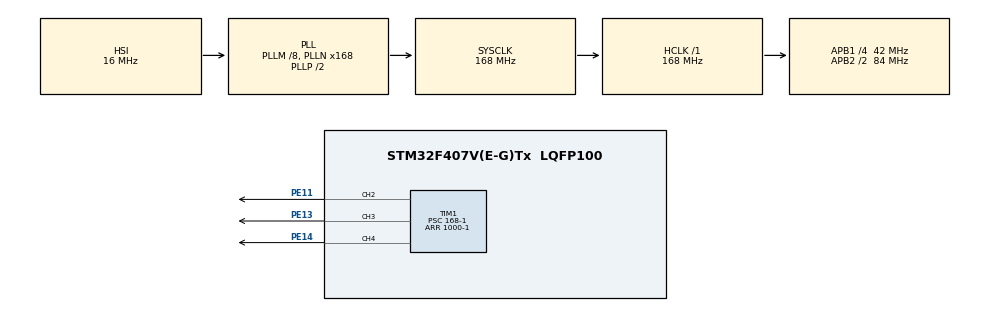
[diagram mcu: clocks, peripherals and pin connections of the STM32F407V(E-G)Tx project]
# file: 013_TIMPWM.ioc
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Mcu.Family=STM32F4
Mcu.Name=STM32F407V(E-G)Tx
Mcu.Package=LQFP100
NVIC.PriorityGroup=NVIC_PRIORITYGROUP_4
PE11.Signal=S_TIM1_CH2
PE13.Signal=S_TIM1_CH3
PE14.Signal=S_TIM1_CH4
ProjectManager.HeapSize=0x200
ProjectManager.StackSize=0x400
ProjectManager.TargetToolchain=EWARM V8.50
RCC.48MHZClocksFreq_Value=84000000
RCC.AHBFreq_Value=168000000
RCC.APB1CLKDivider=RCC_HCLK_DIV4
RCC.APB1Freq_Value=42000000
RCC.APB1TimFreq_Value=84000000
RCC.APB2CLKDivider=RCC_HCLK_DIV2
RCC.APB2Freq_Value=84000000
RCC.APB2TimFreq_Value=168000000
RCC.CortexFreq_Value=168000000
RCC.HCLKFreq_Value=168000000
RCC.HSE_VALUE=25000000
RCC.HSI_VALUE=16000000
RCC.LSE_VALUE=32768
RCC.PLLM=8
RCC.PLLN=168
RCC.SYSCLKFreq_VALUE=168000000
RCC.SYSCLKSource=RCC_SYSCLKSOURCE_PLLCLK
RCC.VCOOutputFreq_Value=336000000
SH.S_TIM1_CH2.0=TIM1_CH2,PWM Generation2 CH2
SH.S_TIM1_CH3.0=TIM1_CH3,PWM Generation3 CH3
SH.S_TIM1_CH4.0=TIM1_CH4,PWM Generation4 CH4
TIM1.Channel-PWM\ Generation2\ CH2=TIM_CHANNEL_2
TIM1.Channel-PWM\ Generation3\ CH3=TIM_CHANNEL_3
TIM1.Channel-PWM\ Generation4\ CH4=TIM_CHANNEL_4
TIM1.Period=1000-1
TIM1.Prescaler=168-1
VP_TIM1_VS_ClockSourceINT.Mode=Internal
board=custom

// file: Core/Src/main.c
/* USER CODE BEGIN Header */
/**
  ******************************************************************************
  * @file           : main.c
  * @brief          : Main program body
  ******************************************************************************
  * @attention
  *
  * Copyright (c) 2026 STMicroelectronics.
  * All rights reserved.
  *
  * This software is licensed under terms that can be found in the LICENSE file
  * in the root directory of this software component.
  * If no LICENSE file comes with this software, it is provided AS-IS.
  *
  ******************************************************************************
  */
/* USER CODE END Header */
#include "main.h"
#include "tim.h"
#include "gpio.h"

/* USER CODE BEGIN PV */

static uint8_t LED0State = 0;
static uint8_t LED1State = 0;
static uint8_t LED2State = 0;

/* USER CODE END PV */

void SystemClock_Config(void);

int main(void)
{

  /* MCU Configuration--------------------------------------------------------*/

  /* Reset of all peripherals, Initializes the Flash interface and the Systick. */
  HAL_Init();

  /* Configure the system clock */
  SystemClock_Config();

  /* Initialize all configured peripherals */
  MX_GPIO_Init();
  MX_TIM1_Init();
  /* USER CODE BEGIN 2 */

  HAL_TIM_PWM_Start_IT(&htim1, TIM_CHANNEL_2);
  HAL_TIM_PWM_Start_IT(&htim1, TIM_CHANNEL_3);
  HAL_TIM_PWM_Start_IT(&htim1, TIM_CHANNEL_4);

  __HAL_TIM_SET_COMPARE(&htim1, TIM_CHANNEL_2, 10);
  __HAL_TIM_SET_COMPARE(&htim1, TIM_CHANNEL_3, 10);
  __HAL_TIM_SET_COMPARE(&htim1, TIM_CHANNEL_4, 10);

  /* USER CODE END 2 */

  /* Infinite loop */
  /* USER CODE BEGIN WHILE */
  while (1)
  {
    // REGISTRY

    TIM1->CCR2 += LED0State ? -1 : 1;
    TIM1->CCR3 += LED1State ? -1 : 1;
    TIM1->CCR4 += LED2State ? -1 : 1;

    if (TIM1->CCR2 == 0 || TIM1->CCR2 == 999) {
      LED0State = !LED0State;
    }
    if (TIM1->CCR3 == 0 || TIM1->CCR3 == 999) {
      LED1State = !LED1State;
    }
    if (TIM1->CCR4 == 0 || TIM1->CCR4 == 999) {
      LED2State = !LED2State;
    }

    // HAL

    /*
    __HAL_TIM_SET_COMPARE(&htim1, TIM_CHANNEL_2, __HAL_TIM_GET_COMPARE(&htim1, TIM_CHANNEL_2) + (LED0State ? -1 : 1));
    __HAL_TIM_SET_COMPARE(&htim1, TIM_CHANNEL_3, __HAL_TIM_GET_COMPARE(&htim1, TIM_CHANNEL_3) + (LED1State ? -1 : 1));
    __HAL_TIM_SET_COMPARE(&htim1, TIM_CHANNEL_4, __HAL_TIM_GET_COMPARE(&htim1, TIM_CHANNEL_4) + (LED2State ? -1 : 1));

    if (__HAL_TIM_GET_COMPARE(&htim1, TIM_CHANNEL_2) == 0 || __HAL_TIM_GET_COMPARE(&htim1, TIM_CHANNEL_2) == 999) {
      LED0State = !LED0State;
    }
    if (__HAL_TIM_GET_COMPARE(&htim1, TIM_CHANNEL_3) == 0 || __HAL_TIM_GET_COMPARE(&htim1, TIM_CHANNEL_3) == 999) {
      LED1State = !LED1State;
    }
    if (__HAL_TIM_GET_COMPARE(&htim1, TIM_CHANNEL_4) == 0 || __HAL_TIM_GET_COMPARE(&htim1, TIM_CHANNEL_4) == 999) {
      LED2State = !LED2State;
    }
    */
    HAL_Delay(1);
    /* USER CODE END WHILE */

  }
}

void SystemClock_Config(void)
{
  RCC_OscInitTypeDef RCC_OscInitStruct = {0};
  RCC_ClkInitTypeDef RCC_ClkInitStruct = {0};

  /** Configure the main internal regulator output voltage
  */
  __HAL_RCC_PWR_CLK_ENABLE();
  __HAL_PWR_VOLTAGESCALING_CONFIG(PWR_REGULATOR_VOLTAGE_SCALE1);

  /** Initializes the RCC Oscillators according to the specified parameters
  * in the RCC_OscInitTypeDef structure.
  */
  RCC_OscInitStruct.OscillatorType = RCC_OSCILLATORTYPE_HSI;
  RCC_OscInitStruct.HSIState = RCC_HSI_ON;
  RCC_OscInitStruct.HSICalibrationValue = RCC_HSICALIBRATION_DEFAULT;
  RCC_OscInitStruct.PLL.PLLState = RCC_PLL_ON;
  RCC_OscInitStruct.PLL.PLLSource = RCC_PLLSOURCE_HSI;
  RCC_OscInitStruct.PLL.PLLM = 8;
  RCC_OscInitStruct.PLL.PLLN = 168;
  RCC_OscInitStruct.PLL.PLLP = RCC_PLLP_DIV2;
  RCC_OscInitStruct.PLL.PLLQ = 4;
  if (HAL_RCC_OscConfig(&RCC_OscInitStruct) != HAL_OK)
  {
    Error_Handler();
  }

  /** Initializes the CPU, AHB and APB buses clocks
  */
  RCC_ClkInitStruct.ClockType = RCC_CLOCKTYPE_HCLK|RCC_CLOCKTYPE_SYSCLK
                              |RCC_CLOCKTYPE_PCLK1|RCC_CLOCKTYPE_PCLK2;
  RCC_ClkInitStruct.SYSCLKSource = RCC_SYSCLKSOURCE_PLLCLK;
  RCC_ClkInitStruct.AHBCLKDivider = RCC_SYSCLK_DIV1;
  RCC_ClkInitStruct.APB1CLKDivider = RCC_HCLK_DIV4;
  RCC_ClkInitStruct.APB2CLKDivider = RCC_HCLK_DIV2;

  if (HAL_RCC_ClockConfig(&RCC_ClkInitStruct, FLASH_LATENCY_5) != HAL_OK)
  {
    Error_Handler();
  }
}

void Error_Handler(void)
{
  __disable_irq();
  while (1)
  {
  }
}
